# STM32WL5X_CM0P register map
File version: 2.1
CPU: CM0 r0p1, little endian, MPU, no FPU, 4 interrupt priority bits
Registers are 32-bit, read-write, reset 0x0 unless marked. A register's access mark holds for its fields unless they carry their own. Offsets are from the block's base; [hi:lo] are bit positions; {n}, {i} and the like mark numbered series; 'fields as' and 'values as' point back to an identical list.

## RCC — Reset and clock control
Base 0x58000000
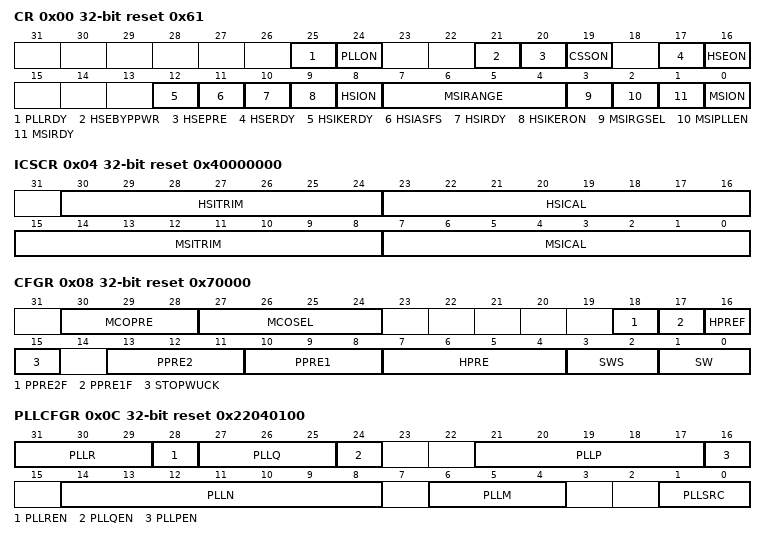
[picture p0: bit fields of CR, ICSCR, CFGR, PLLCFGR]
0x00 CR access per field reset 0x61 — Clock control register
  [25] PLLRDY ro — Main PLL clock ready flag
    0=Unlocked (PLL unlocked); 1=Locked (PLL Locked)
  [24] PLLON rw — Main PLL enable
    0=Off (Main PLL Off); 1=On (Main PLL On)
  [21] HSEBYPPWR rw — Enable HSE32 VDDTCXO output on package pin PB0-VDDTCXO.
    0=PB0 (PB0 selected); 1=VDDTCXO (VDDTCXO selected)
  [20] HSEPRE rw — HSE32 sysclk prescaler
    0=Div1 (SYSCLK not divided (HSE32)); 1=Div2 (SYSCLK divided by two (HSE32/2))
  [19] CSSON rw — HSE32 Clock security system enable
    0=Disabled (HSE32 CSS off); 1=Enabled (HSE32 CSS on if the HSE32 oscillator is stable and off if not)
  [17] HSERDY ro — HSE32 clock ready flag
    0=NotReady (HSE32 oscillator not ready); 1=Ready (HSE32 oscillator ready)
  [16] HSEON rw — HSE32 clock enable
    0=Disabled (HSE32 oscillator for CPU disabled); 1=Enabled (HSE32 oscillator for CPU enabled)
  [12] HSIKERDY ro — HSI16 kernel clock ready flag for peripherals requests.
    0=NotReady (HSI16 oscillator not ready); 1=Ready (HSI16 oscillator ready)
  [11] HSIASFS rw — HSI16 automatic start from Stop
    0=Disabled (HSI16 not enabled by hardware when exiting Stop modes with MSI as wakeup clock); 1=Enabled (HSI16 enabled by hardware when exiting Stop mode with MSI as wakeup clock)
  [10] HSIRDY ro — HSI16 clock ready flag. (After wakeup from Stop this bit will be read 1 once the HSI16 is ready)
    values as HSIKERDY
  [9] HSIKERON rw — HSI16 always enable for peripheral kernel clocks.
    0=NotForced (No effect on HSI16 oscillator); 1=Forced (HSI16 oscillator forced on even in Stop modes)
  [8] HSION rw — HSI16 clock enable
    0=Disabled (HSI16 oscillator off); 1=Enabled (HSI16 oscillator on)
  [7:4] MSIRANGE rw — MSI clock ranges
    0=Range100K (range 0 around 100 kHz); 1=Range200K (range 1 around 200 kHz); 2=Range400K (range 2 around 400 kHz); 3=Range800K (range 3 around 800 kHz); 4=Range1M (range 4 around 1 MHz); 5=Range2M (range 5 around 2 MHz); 6=Range4M (range 6 around 4 MHz (reset value)); 7=Range8M (range 7 around 8 MHz); 8=Range16M (range 8 around 16 MHz); 9=Range24M (range 9 around 24 MHz); 10=Range32M (range 10 around 32 MHz); 11=Range48M (range 11 around 48 MHz)
  [3] MSIRGSEL rw — MSI range control selection
    0=CSR (MSI frequency range defined by MSISRANGE[3:0] in the RCC_CSR register); 1=CR (MSI frequency range defined by MSIRANGE[3:0] in the RCC_CR register)
  [2] MSIPLLEN rw — MSI clock PLL enable
    0=Off (MSI PLL Off); 1=On (MSI PLL On)
  [1] MSIRDY ro — MSI clock ready flag (After reset this bit will be read 1 once the MSI is ready)
    0=NotReady (MSI oscillator not ready); 1=Ready (MSI oscillator ready)
  [0] MSION rw — MSI clock enable
    0=Disabled (MSI oscillator off); 1=Enabled (MSI oscillator on)
0x04 ICSCR access per field reset 0x40000000 — Internal clock sources calibration register
  [30:24] HSITRIM rw range 0..63 — HSI16 clock trimming
  [23:16] HSICAL ro — HSI16 clock calibration
  [15:8] MSITRIM rw — MSI clock trimming
  [7:0] MSICAL ro — MSI clock calibration
0x08 CFGR access per field reset 0x70000 — Clock configuration register
  [30:28] MCOPRE rw — Microcontroller clock output prescaler
    0=Div1 (No division); 1=Div2 (Division by 2); 2=Div4 (Division by 4); 3=Div8 (Division by 8); 4=Div16 (Division by 16)
  [27:24] MCOSEL rw — Microcontroller clock output
    0=NoClock; 1=SYSCLK (SYSCLK clock selected); 2=MSI (MSI oscillator clock selected); 3=HSI16 (HSI16 oscillator clock selected); 4=HSE32 (HSE32 oscillator clock selected); 5=PLLR (Main PLLRCLK clock selected); 6=LSI (LSI oscillator clock selected); 8=LSE (LSE oscillator clock selected); 13=PLLP (Main PLLPCLK clock selected); 14=PLLQ (Main PLLQCLK clock selected)
  [18] PPRE2F ro — PCLK2 prescaler flag (APB2)
    0=NotApplied (PCLK2 prescaler value not yet applied); 1=Applied (PCLK2 prescaler value applied)
  [17] PPRE1F ro — PCLK1 prescaler flag (APB1)
    0=NotApplied (PCLK1 prescaler value not yet applied); 1=Applied (PCLK1 prescaler value applied)
  [16] HPREF ro — HCLK1 prescaler flag (CPU1, AHB1, AHB2, and SRAM1)
    0=NotApplied (HCLK1 prescaler value not yet applied); 1=Applied (HCLK1 prescaler value applied)
  [15] STOPWUCK rw — Wakeup from Stop and CSS backup clock selection
    0=MSI (MSI oscillator selected as wakeup from stop clock and CSS backup clock); 1=HSI16 (HSI16 oscillator selected as wakeup from stop clock and CSS backup clock)
  [13:11] PPRE2 rw — PCLK2 high-speed prescaler (APB2)
    4=Div2 (HCLK divided by 2); 5=Div4 (HCLK divided by 4); 6=Div8 (HCLK divided by 8); 7=Div16 (HCLK divided by 16); other=Div1 (HCLK not divided)
  [10:8] PPRE1 rw — PCLK1 low-speed prescaler (APB1)
    values as PPRE2
  [7:4] HPRE rw — HCLK1 prescaler (CPU1, AHB1, AHB2, and SRAM1.)
    1=Div3 (SYSCLK divided by 3); 2=Div5 (SYSCLK divided by 5); 5=Div6 (SYSCLK divided by 6); 6=Div10 (SYSCLK divided by 10); 7=Div32 (SYSCLK divided by 32); 8=Div2 (SYSCLK divided by 2); 9=Div4 (SYSCLK divided by 4); 10=Div8 (SYSCLK divided by 8); 11=Div16 (SYSCLK divided by 16); 12=Div64 (SYSCLK divided by 64); 13=Div128 (SYSCLK divided by 128); 14=Div256 (SYSCLK divided by 256); 15=Div512 (SYSCLK divided by 512); other=Div1 (SYSCLK not divided)
  [3:2] SWS ro — System clock switch status
    0=MSI (MSI oscillator used as system clock); 1=HSI16 (HSI16 oscillator used as system clock); 2=HSE32 (HSE32 oscillator used as system clock); 3=PLLR (PLLRCLK used as system clock)
  [1:0] SW rw — System clock switch
    values as SWS
0x0C PLLCFGR reset 0x22040100 — PLL configuration register
  [31:29] PLLR — Main PLL division factor for PLLRCLK
    {v}=Div{v+1} (PLL = VCO/(N+1)) (v=1..7)
  [28] PLLREN — Main PLL PLLRCLK output enable
    0=Disabled (PLLCLK output disabled); 1=Enabled (PLLCLK output enabled)
  [27:25] PLLQ — Main PLL division factor for PLLQCLK
    {v}=Div{v+1} (PLL = VCO/(N+1)) (v=1..7)
  [24] PLLQEN — Main PLL PLLQCLK output enable
    values as PLLREN
  [21:17] PLLP — Main PLL division factor for PLLPCLK.
    {v}=Div{v+1} (PLL = VCO/(N+1)) (v=1..31)
  [16] PLLPEN — Main PLL PLLPCLK output enable
    values as PLLREN
  [14:8] PLLN range 6..127 — Main PLL multiplication factor for VCO
  [6:4] PLLM — Division factor for the main PLL input clock
    {v}=Div{v+1} (VCO input = PLL input / PLLM) (v=0..7)
  [1:0] PLLSRC — Main PLL entry clock source
    0=No clock sent to PLL; 1=MSI (MSI clock selected as PLL clock entry); 2=HSI16 (HSI16 clock selected as PLL clock entry); 3=HSE32 (HSE32 clock selected as PLL clock entry)
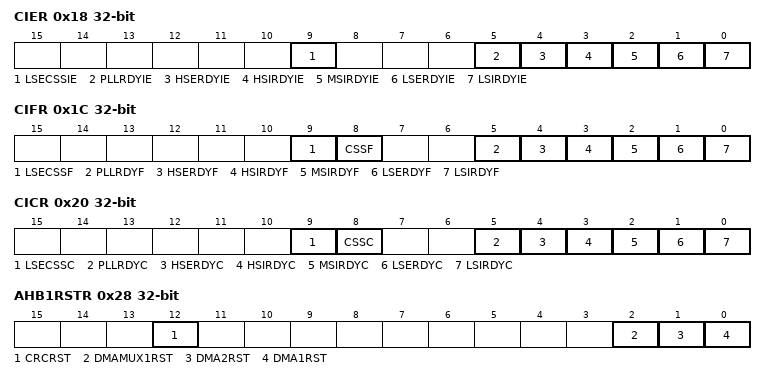
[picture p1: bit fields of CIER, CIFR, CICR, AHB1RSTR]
0x18 CIER — Clock interrupt enable register
  [all] fields
    0=Disabled (Interrupt disabled); 1=Enabled (Interrupt enabled)
  [9] LSECSSIE — LSE clock security system interrupt enable
  [5] PLLRDYIE — PLL ready interrupt enable
  [4] HSERDYIE — HSE32 ready interrupt enable
  [3] HSIRDYIE — HSI16 ready interrupt enable
  [2] MSIRDYIE — MSI ready interrupt enable
  [1] LSERDYIE — LSE ready interrupt enable
  [0] LSIRDYIE — LSI ready interrupt enable
0x1C CIFR ro — Clock interrupt flag register
  [all] fields
    0=NotInterrupted; 1=Interrupted
  [9] LSECSSF — LSE Clock security system interrupt flag
  [8] CSSF — HSE32 Clock security system interrupt flag
  [5] PLLRDYF — PLL ready interrupt flag
  [4] HSERDYF — HSE32 ready interrupt flag
  [3] HSIRDYF — HSI16 ready interrupt flag
  [2] MSIRDYF — MSI ready interrupt flag
  [1] LSERDYF — LSE ready interrupt flag
  [0] LSIRDYF — LSI ready interrupt flag
0x20 CICR wo — Clock interrupt clear register
  [all] fields
    1=Clear interrupt flag
  [9] LSECSSC — LSE Clock security system interrupt clear
  [8] CSSC — HSE32 Clock security system interrupt clear
  [5] PLLRDYC — PLL ready interrupt clear
  [4] HSERDYC — HSE32 ready interrupt clear
  [3] HSIRDYC — HSI16 ready interrupt clear
  [2] MSIRDYC — MSI ready interrupt clear
  [1] LSERDYC — LSE ready interrupt clear
  [0] LSIRDYC — LSI ready interrupt clear
0x28 AHB1RSTR — AHB1 peripheral reset register
  [all] fields
    0=NoReset (No effect); 1=Reset peripheral
  [12] CRCRST — CRC reset
  [2] DMAMUX1RST — DMAMUX1 reset
  [1] DMA2RST — DMA2 reset
  [0] DMA1RST — DMA1 reset
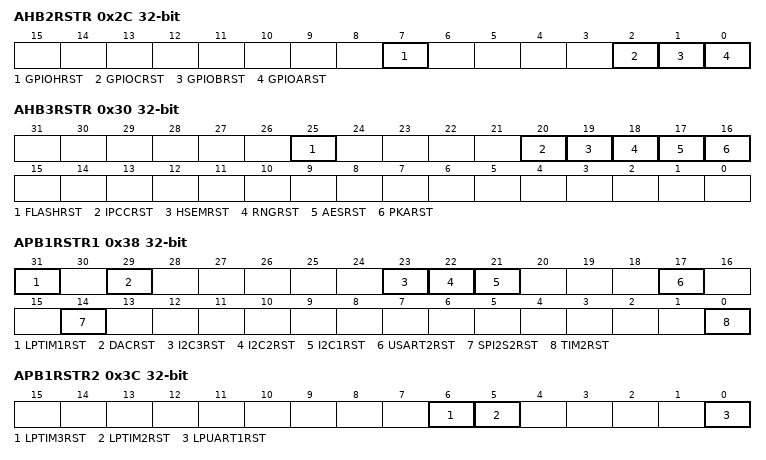
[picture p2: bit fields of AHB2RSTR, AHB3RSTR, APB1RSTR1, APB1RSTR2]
0x2C AHB2RSTR — AHB2 peripheral reset register
  [all] fields
    0=NoReset (No effect); 1=Reset peripheral
  [7] GPIOHRST — IO port H reset
  [2] GPIOCRST — IO port C reset
  [1] GPIOBRST — IO port B reset
  [0] GPIOARST — IO port A reset
0x30 AHB3RSTR — AHB3 peripheral reset register
  [all] fields
    0=NoReset (No effect); 1=Reset peripheral
  [25] FLASHRST — Flash interface reset
  [20] IPCCRST
  [19] HSEMRST
  [18] RNGRST
  [17] AESRST
  [16] PKARST
0x38 APB1RSTR1 — APB1 peripheral reset register 1
  [all] fields
    0=NoReset (No effect); 1=Reset peripheral
  [31] LPTIM1RST — Low Power Timer 1 reset
  [29] DACRST — DAC1 reset
  [23] I2C3RST — I2C3 reset
  [22] I2C2RST — I2C2 reset
  [21] I2C1RST — I2C1 reset
  [17] USART2RST — USART2 reset
  [14] SPI2S2RST — SPI2S2 reset
  [0] TIM2RST — TIM2 timer reset
0x3C APB1RSTR2 — APB1 peripheral reset register 2
  [all] fields
    0=NoReset (No effect); 1=Reset peripheral
  [6] LPTIM3RST — Low-power timer 3 reset
  [5] LPTIM2RST — Low-power timer 2 reset
  [0] LPUART1RST — Low-power UART 1 reset
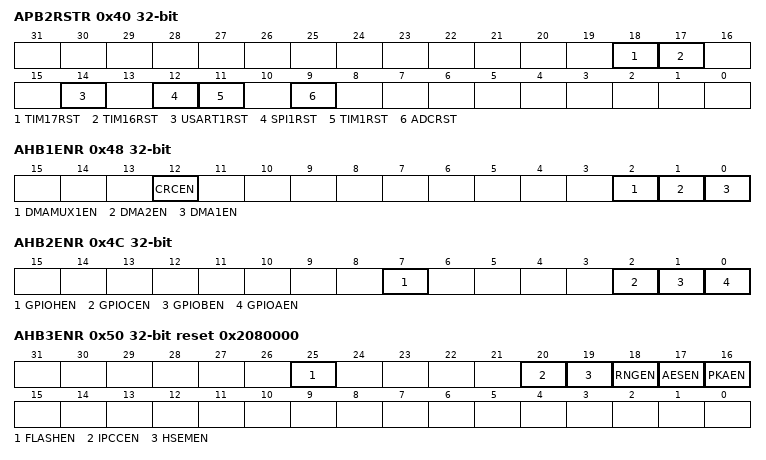
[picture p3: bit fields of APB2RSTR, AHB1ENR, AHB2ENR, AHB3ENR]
0x40 APB2RSTR — APB2 peripheral reset register
  [18] TIM17RST — TIM17 timer reset
  [17] TIM16RST — TIM16 timer reset
  [14] USART1RST — USART1 reset
  [12] SPI1RST — SPI1 reset
  [11] TIM1RST — TIM1 timer reset
  [9] ADCRST — ADC reset
0x44 APB3RSTR — APB3 peripheral reset register
  [0] SUBGHZSPIRST — Sub-GHz radio SPI reset
0x48 AHB1ENR — AHB1 peripheral clock enable register
  [all] fields
    0=Disabled (Clock disabled); 1=Enabled (Clock enabled)
  [12] CRCEN — CPU1 CRC clock enable
  [2] DMAMUX1EN — CPU1 DMAMUX1 clock enable
  [1] DMA2EN — CPU1 DMA2 clock enable
  [0] DMA1EN — CPU1 DMA1 clock enable
0x4C AHB2ENR — AHB2 peripheral clock enable register
  [all] fields
    0=Disabled (Clock disabled); 1=Enabled (Clock enabled)
  [7] GPIOHEN — CPU1 IO port H clock enable
  [2] GPIOCEN — CPU1 IO port C clock enable
  [1] GPIOBEN — CPU1 IO port B clock enable
  [0] GPIOAEN — CPU1 IO port A clock enable
0x50 AHB3ENR reset 0x2080000 — AHB3 peripheral clock enable register
  [all] fields
    0=Disabled (Clock disabled); 1=Enabled (Clock enabled)
  [25] FLASHEN — CPU1 Flash interface clock enable
  [20] IPCCEN
  [19] HSEMEN
  [18] RNGEN
  [17] AESEN
  [16] PKAEN
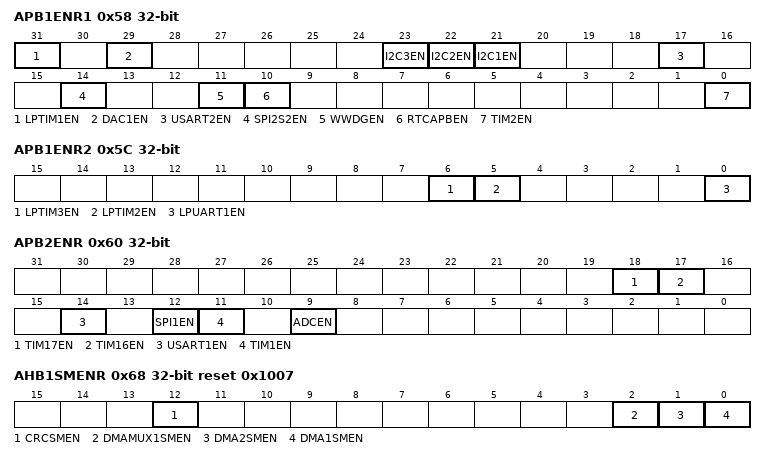
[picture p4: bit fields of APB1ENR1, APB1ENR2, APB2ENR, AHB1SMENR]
0x58 APB1ENR1 — APB1 peripheral clock enable register 1
  [all] fields
    0=Disabled (Clock disabled); 1=Enabled (Clock enabled)
  [31] LPTIM1EN — CPU1 Low power timer 1 clocks enable
  [29] DAC1EN — CPU1 DAC1 clock enable
  [23] I2C3EN — CPU1 I2C3 clocks enable
  [22] I2C2EN — CPU1 I2C2 clocks enable
  [21] I2C1EN — CPU1 I2C1 clocks enable
  [17] USART2EN — CPU1 USART2 clock enable
  [14] SPI2S2EN — CPU1 SPI2S2 clock enable
  [11] WWDGEN — CPU1 Window watchdog clock enable
  [10] RTCAPBEN — CPU1 RTC APB clock enable
  [0] TIM2EN — CPU1 TIM2 timer clock enable
0x5C APB1ENR2 — APB1 peripheral clock enable register 2
  [all] fields
    0=Disabled (Clock disabled); 1=Enabled (Clock enabled)
  [6] LPTIM3EN — CPU1 Low power timer 3 clocks enable
  [5] LPTIM2EN — CPU1 Low power timer 2 clocks enable
  [0] LPUART1EN — CPU1 Low power UART 1 clocks enable
0x60 APB2ENR — APB2 peripheral clock enable register
  [all] fields
    0=Disabled (Clock disabled); 1=Enabled (Clock enabled)
  [18] TIM17EN — CPU1 TIM17 timer clock enable
  [17] TIM16EN — CPU1 TIM16 timer clock enable
  [14] USART1EN — CPU1 USART1clocks enable
  [12] SPI1EN — CPU1 SPI1 clock enable
  [11] TIM1EN — CPU1 TIM1 timer clock enable
  [9] ADCEN — CPU1 ADC clocks enable
0x64 APB3ENR — APB3 peripheral clock enable register
  [0] SUBGHZSPIEN — sub-GHz radio SPI clock enable
    0=Disabled (Clock disabled); 1=Enabled (Clock enabled)
0x68 AHB1SMENR reset 0x1007 — AHB1 peripheral clocks enable in Sleep modes register
  [12] CRCSMEN — CRC clock enable during CPU1 CSleep mode.
  [2] DMAMUX1SMEN — DMAMUX1 clock enable during CPU1 CSleep mode.
  [1] DMA2SMEN — DMA2 clock enable during CPU1 CSleep mode
  [0] DMA1SMEN — DMA1 clock enable during CPU1 CSleep mode.
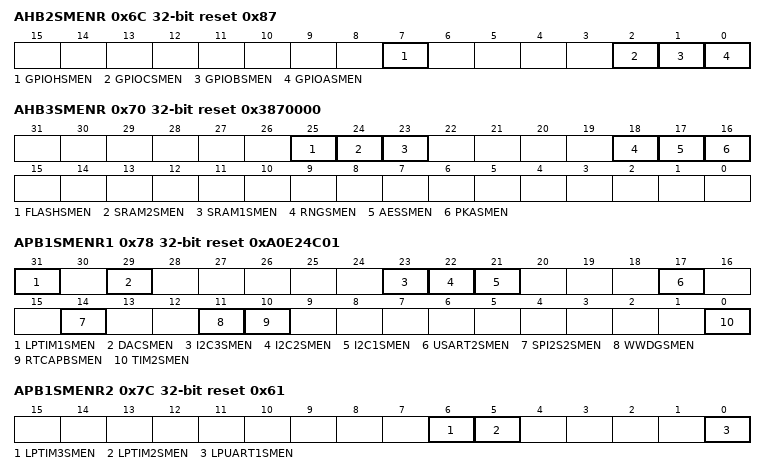
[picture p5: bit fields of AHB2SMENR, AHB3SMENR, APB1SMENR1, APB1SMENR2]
0x6C AHB2SMENR reset 0x87 — AHB2 peripheral clocks enable in Sleep modes register
  [7] GPIOHSMEN — IO port H clock enable during CPU1 CSleep mode.
  [2] GPIOCSMEN — IO port C clock enable during CPU1 CSleep mode.
  [1] GPIOBSMEN — IO port B clock enable during CPU1 CSleep mode.
  [0] GPIOASMEN — IO port A clock enable during CPU1 CSleep mode.
0x70 AHB3SMENR reset 0x3870000 — AHB3 peripheral clocks enable in Sleep and Stop modes register
  [25] FLASHSMEN — Flash interface clock enable during CPU1 CSleep mode.
  [24] SRAM2SMEN — SRAM2 memory interface clock enable during CPU1 CSleep mode
  [23] SRAM1SMEN — SRAM1 interface clock enable during CPU1 CSleep mode.
  [18] RNGSMEN — True RNG clocks enable during CPU1 Csleep and CStop modes
  [17] AESSMEN — AES accelerator clock enable during CPU1 CSleep mode.
  [16] PKASMEN — PKA accelerator clock enable during CPU1 CSleep mode.
0x78 APB1SMENR1 reset 0xA0E24C01 — APB1 peripheral clocks enable in Sleep mode register 1
  [all] fields
    0=Disabled (Clock disabled); 1=Enabled (Clock enabled)
  [31] LPTIM1SMEN — Low power timer 1 clock enable during CPU1 Csleep and CStop mode
  [29] DACSMEN — DAC1 clock enable during CPU1 CSleep mode.
  [23] I2C3SMEN — I2C3 clock enable during CPU1 Csleep and CStop modes
  [22] I2C2SMEN — I2C2 clock enable during CPU1 Csleep and CStop modes
  [21] I2C1SMEN — I2C1 clock enable during CPU1 Csleep and CStop modes
  [17] USART2SMEN — USART2 clock enable during CPU1 CSleep mode.
  [14] SPI2S2SMEN — SPI2S2 clock enable during CPU1 CSleep mode.
  [11] WWDGSMEN — Window watchdog clocks enable during CPU1 CSleep mode.
  [10] RTCAPBSMEN — RTC bus clock enable during CPU1 CSleep mode.
  [0] TIM2SMEN — TIM2 timer clock enable during CPU1 CSleep mode.
0x7C APB1SMENR2 reset 0x61 — APB1 peripheral clocks enable in Sleep mode register 2
  [all] fields
    0=Disabled (Clock disabled); 1=Enabled (Clock enabled)
  [6] LPTIM3SMEN — Low power timer 3 clock enable during CPU1 Csleep and CStop modes
  [5] LPTIM2SMEN — Low power timer 2 clock enable during CPU1 Csleep and CStop modes
  [0] LPUART1SMEN — Low power UART 1 clock enable during CPU1 Csleep and CStop modes.
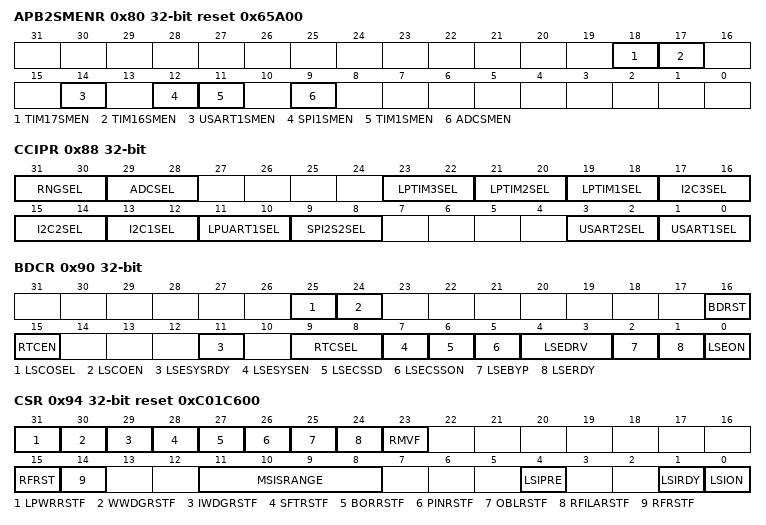
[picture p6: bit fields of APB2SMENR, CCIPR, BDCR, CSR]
0x80 APB2SMENR reset 0x65A00 — APB2 peripheral clocks enable in Sleep mode register
  [18] TIM17SMEN — TIM17 timer clock enable during CPU1 CSleep mode.
  [17] TIM16SMEN — TIM16 timer clock enable during CPU1 CSleep mode.
  [14] USART1SMEN — USART1 clock enable during CPU1 Csleep and CStop modes.
  [12] SPI1SMEN — SPI1 clock enable during CPU1 CSleep mode.
  [11] TIM1SMEN — TIM1 timer clock enable during CPU1 CSleep mode.
  [9] ADCSMEN — ADC clocks enable during CPU1 Csleep and CStop modes
0x84 APB3SMENR reset 0x1 — APB3 peripheral clock enable in Sleep mode register
  [0] SUBGHZSPISMEN — Sub-GHz radio SPI clock enable during Sleep and Stop modes
0x88 CCIPR — Peripherals independent clock configuration register
  [31:30] RNGSEL — RNG clock source selection
    0=PLLQ (PLLQ clock selected); 1=LSI (LSI clock selected); 2=LSE (LSE clock selected); 3=MSI (MSI clock selected)
  [29:28] ADCSEL — ADC clock source selection
    0=No clock selected; 1=HSI16 (HSI16 clock selected); 2=PLLP (PLLP clock selected); 3=SYSCLK (SYSCLK clock selected)
  [23:22] LPTIM3SEL — Low power timer 3 clock source selection
    0=PCLK (PCLK clock selected); 1=LSI (LSI clock selected); 2=HSI16 (HSI16 clock selected); 3=LSE (LSE clock selected)
  [21:20] LPTIM2SEL — Low power timer 2 clock source selection
    values as LPTIM3SEL
  [19:18] LPTIM1SEL — Low power timer 1 clock source selection
    values as LPTIM3SEL
  [17:16] I2C3SEL — I2C3 clock source selection
    0=PCLK (PCLK clock selected); 1=SYSCLK (SYSCLK clock selected); 2=HSI16 (HSI16 clock selected)
  [15:14] I2C2SEL — I2C2 clock source selection
    values as I2C3SEL
  [13:12] I2C1SEL — I2C1 clock source selection
    values as I2C3SEL
  [11:10] LPUART1SEL — LPUART1 clock source selection
    0=PCLK (PCLK clock selected); 1=SYSCLK (SYSCLK clock selected); 2=HSI16 (HSI16 clock selected); 3=LSE (LSE clock selected)
  [9:8] SPI2S2SEL — SPI2S2 I2S clock source selection
    1=PLLQ (PLLQ clock selected); 2=HSI16 (HSI16 clock selected); 3=I2S (External input I2S_CKIN selected)
  [3:2] USART2SEL — USART2 clock source selection
    values as LPUART1SEL
  [1:0] USART1SEL — USART1 clock source selection
    values as LPUART1SEL
0x90 BDCR access per field — Backup domain control register
  [25] LSCOSEL rw — Low speed clock output selection
    0=LSI (LSI clock selected); 1=LSE (LSE clock selected)
  [24] LSCOEN rw — Low speed clock output enable
    0=Disabled (LSCO disabled); 1=Enabled (LSCO enabled)
  [16] BDRST rw — Backup domain software reset
    0=NotActive (Reset not activated); 1=Reset (Entire Backup domain reset)
  [15] RTCEN rw — RTC clock enable
    0=Disabled (RTC kernel clock disabled); 1=Enabled (RTC kernel clock enabled)
  [11] LSESYSRDY ro — LSE system clock ready
    0=NotReady (LSE system clock not ready); 1=Ready (LSE system clock ready)
  [9:8] RTCSEL rw — RTC clock source selection
    0=NoClock; 1=LSE (LSE oscillator clock selected); 2=LSI (LSI oscillator clock selected); 3=HSE32 (HSE32 oscillator clock divided by 32 selected)
  [7] LSESYSEN rw — LSE system clock enable
    0=Disabled (LSE system clock disabled to USARTx, LPUARTx, LPTIMx, TIMx, RNG, system LSCO, MCO, MSI PLL mode); 1=Enabled (LSE system clock enabled to USARTx, LPUARTx, LPTIMx, TIMx, RNG, system LSCO, MCO, MSI PLL mode)
  [6] LSECSSD ro — CSS on LSE failure Detection
    0=No failure detected on LSE; 1=Failure detected on LSE
  [5] LSECSSON rw — CSS on LSE enable
    0=Disabled (CSS on LSE disabled); 1=Enabled (CSS on LSE enabled)
  [4:3] LSEDRV rw — LSE oscillator drive capability
    0=Low (Xtal mode lower driving capability); 1=MedLow (Xtal mode medium-low driving capability); 2=MedHigh (Xtal mode medium-high driving capability); 3=High (Xtal mode higher driving capability)
  [2] LSEBYP rw — LSE oscillator bypass
    0=Disabled (LSE oscillator not bypassed); 1=Enabled (LSE oscillator bypassed)
  [1] LSERDY ro — LSE oscillator ready
    0=NotReady (LSE oscillator not ready); 1=Ready (LSE oscillator ready)
  [0] LSEON rw — LSE oscillator enable
    0=Off (LSE oscillator off); 1=On (LSE oscillator on)
0x94 CSR access per field reset 0xC01C600 — Control/status register
  [31] LPWRRSTF ro — Low-power reset flag
    0=No reset occurred; 1=Reset occurred
  [30] WWDGRSTF ro — Window watchdog reset flag
    0=No reset occurred; 1=Reset occurred
  [29] IWDGRSTF ro — Independent window watchdog reset flag
    0=No reset occurred; 1=Reset occurred
  [28] SFTRSTF ro — Software reset flag
    0=No reset occurred; 1=Reset occurred
  [27] BORRSTF ro — BOR flag
    0=No reset occurred; 1=Reset occurred
  [26] PINRSTF ro — Pin reset flag
    0=No reset occurred; 1=Reset occurred
  [25] OBLRSTF ro — Option byte loader reset flag
    0=No reset occurred; 1=Reset occurred
  [24] RFILARSTF ro — Radio illegal access flag
    0=NoIllegalCommand (No SUBGHZ radio illegal command occurred); 1=IllegalCommand (SUBGHZ radio illegal command occurred)
  [23] RMVF rw — Remove reset flag
    0=NoEffect; 1=Clear (Reset flags reset)
  [15] RFRST rw — Radio reset
    0=Removed (Sub-GHz radio software reset removed); 1=Reset (Sub-GHz radio software reset active)
  [14] RFRSTF ro — Radio in reset status flag
    0=NoReset (Sub-GHz radio out of reset); 1=Reset (Sub-GHz radio in reset)
  [11:8] MSISRANGE rw — MSI clock ranges
    4=f_1MHz (Range 4 around 1 MHz); 5=f_2MHz (Range 5 around 2 MHz); 6=f_4MHz (Range 6 around 4 MHz (reset value)); 7=f_8MHz (Range 7 around 8 MHz)
  [4] LSIPRE rw — LSI frequency prescaler
    0=Div1 (LSI clock not divided); 1=Div128 (LSI clock divided by 128)
  [1] LSIRDY ro — LSI oscillator ready
    0=NotReady (LSI oscillator not ready); 1=Ready (LSI oscillator ready)
  [0] LSION rw — LSI oscillator enable
    0=Off (LSI oscillator off); 1=On (LSI oscillator on)
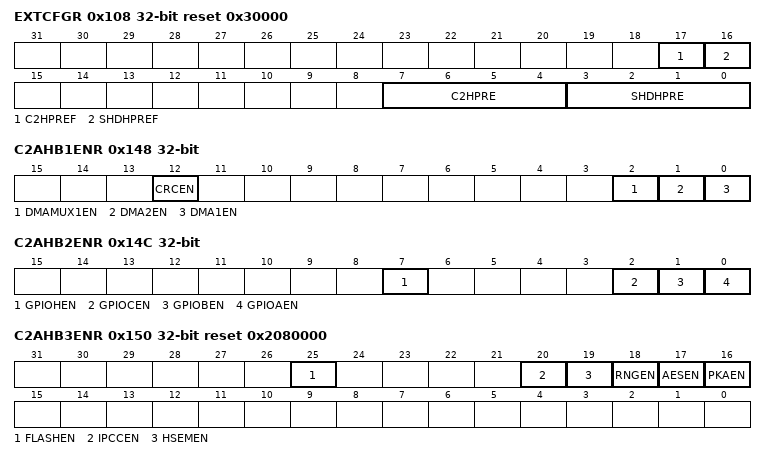
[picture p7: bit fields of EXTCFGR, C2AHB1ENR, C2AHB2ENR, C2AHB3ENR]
0x108 EXTCFGR access per field reset 0x30000 — Extended clock recovery register
  [17] C2HPREF ro — CLK2 prescaler flag (CPU2)
  [16] SHDHPREF ro — HCLK3 shared prescaler flag (AHB3, Flash, and SRAM2)
    0=NotApplied (HCLK3 prescaler value not yet applied); 1=Applied (HCLK3 prescaler value applied)
  [7:4] C2HPRE rw — [dual core device only] HCLK2 prescaler (CPU2)
  [3:0] SHDHPRE rw — HCLK3 shared prescaler (AHB3, Flash, and SRAM2)
    values as CFGR.HPRE
0x148 C2AHB1ENR — CPU2 AHB1 peripheral clock enable register
  [all] fields
    0=Disabled (Clock disabled); 1=Enabled (Clock enabled)
  [12] CRCEN — CPU2 CRC clock enable
  [2] DMAMUX1EN — CPU2 DMAMUX1 clock enable
  [1] DMA2EN — CPU2 DMA2 clock enable
  [0] DMA1EN — CPU2 DMA1 clock enable
0x14C C2AHB2ENR — CPU2 AHB2 peripheral clock enable register
  [all] fields
    0=Disabled (Clock disabled); 1=Enabled (Clock enabled)
  [7] GPIOHEN — CPU2 IO port H clock enable
  [2] GPIOCEN — CPU2 IO port C clock enable
  [1] GPIOBEN — CPU2 IO port B clock enable
  [0] GPIOAEN — CPU2 IO port A clock enable
0x150 C2AHB3ENR reset 0x2080000 — CPU2 AHB3 peripheral clock enable register [dual core device only]
  [all] fields
    0=Disabled (Clock disabled); 1=Enabled (Clock enabled)
  [25] FLASHEN — CPU2 Flash interface clock enable
  [20] IPCCEN — CPU2 IPCC interface clock enable
  [19] HSEMEN — CPU2 HSEM clock enable
  [18] RNGEN — CPU2 True RNG clocks enable
  [17] AESEN — CPU2 AES accelerator clock enable
  [16] PKAEN — CPU2 PKA accelerator clock enable
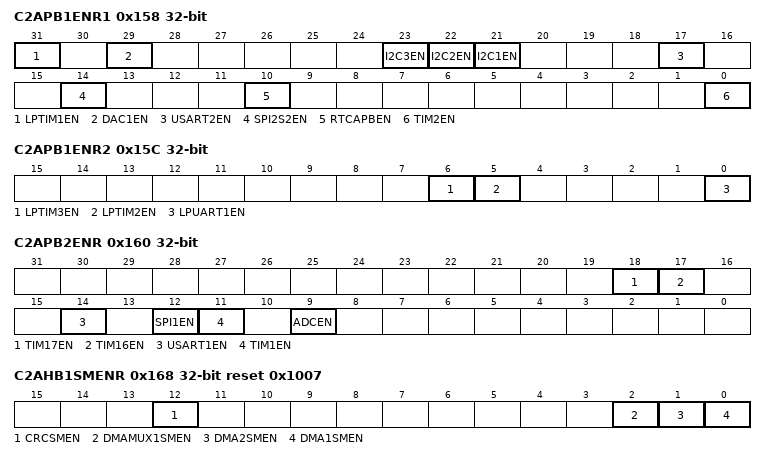
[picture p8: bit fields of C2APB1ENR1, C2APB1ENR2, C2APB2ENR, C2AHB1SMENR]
0x158 C2APB1ENR1 — CPU2 APB1 peripheral clock enable register 1 [dual core device only]
  [all] fields
    0=Disabled (Clock disabled); 1=Enabled (Clock enabled)
  [31] LPTIM1EN — CPU2 Low power timer 1 clocks enable
  [29] DAC1EN — CPU2 DAC1 clock enable
  [23] I2C3EN — CPU2 I2C3 clocks enable
  [22] I2C2EN — CPU2 I2C2 clocks enable
  [21] I2C1EN — CPU2 I2C1 clocks enable
  [17] USART2EN — CPU2 USART2 clock enable
  [14] SPI2S2EN — CPU2 SPI2S2 clock enable
  [10] RTCAPBEN — CPU2 RTC APB clock enable
  [0] TIM2EN — CPU2 TIM2 timer clock enable
0x15C C2APB1ENR2 — CPU2 APB1 peripheral clock enable register 2 [dual core device only]
  [all] fields
    0=Disabled (Clock disabled); 1=Enabled (Clock enabled)
  [6] LPTIM3EN — CPU2 Low power timer 3 clocks enable
  [5] LPTIM2EN — CPU2 Low power timer 2 clocks enable
  [0] LPUART1EN — CPU2 Low power UART 1 clocks enable
0x160 C2APB2ENR — CPU2 APB2 peripheral clock enable register [dual core device only]
  [all] fields
    0=Disabled (Clock disabled); 1=Enabled (Clock enabled)
  [18] TIM17EN — CPU2 TIM17 timer clock enable
  [17] TIM16EN — CPU2 TIM16 timer clock enable
  [14] USART1EN — CPU2 USART1clocks enable
  [12] SPI1EN — CPU2 SPI1 clock enable
  [11] TIM1EN — CPU2 TIM1 timer clock enable
  [9] ADCEN — ADC clocks enable
0x164 C2APB3ENR — CPU2 APB3 peripheral clock enable register [dual core device only]
  [0] SUBGHZSPIEN — CPU2 sub-GHz radio SPI clock enable
    0=Disabled (Clock disabled); 1=Enabled (Clock enabled)
0x168 C2AHB1SMENR reset 0x1007 — CPU2 AHB1 peripheral clocks enable in Sleep modes register [dual core device only]
  [all] fields
    0=Disabled (Clock disabled); 1=Enabled (Clock enabled)
  [12] CRCSMEN — CRC clock enable during CPU2 CSleep mode.
  [2] DMAMUX1SMEN — DMAMUX1 clock enable during CPU2 CSleep mode.
  [1] DMA2SMEN — DMA2 clock enable during CPU2 CSleep mode.
  [0] DMA1SMEN — DMA1 clock enable during CPU2 CSleep mode.
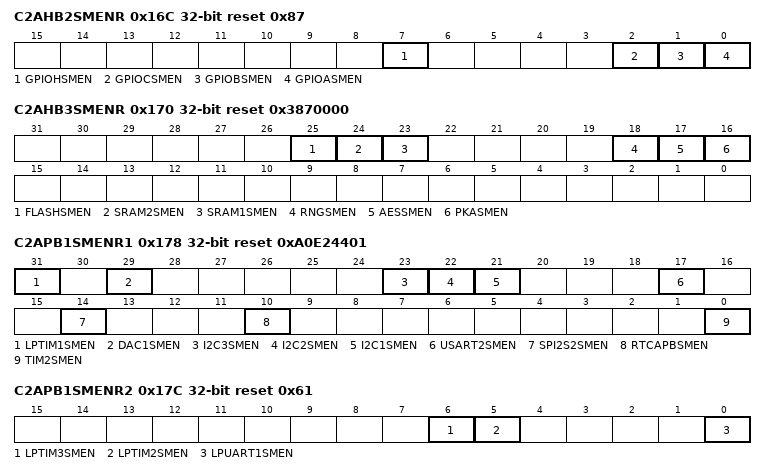
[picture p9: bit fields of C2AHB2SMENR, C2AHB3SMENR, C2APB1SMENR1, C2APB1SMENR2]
0x16C C2AHB2SMENR reset 0x87 — CPU2 AHB2 peripheral clocks enable in Sleep modes register [dual core device only]
  [all] fields
    0=Disabled (Clock disabled); 1=Enabled (Clock enabled)
  [7] GPIOHSMEN — IO port H clock enable during CPU2 CSleep mode.
  [2] GPIOCSMEN — IO port C clock enable during CPU2 CSleep mode.
  [1] GPIOBSMEN — IO port B clock enable during CPU2 CSleep mode.
  [0] GPIOASMEN — IO port A clock enable during CPU2 CSleep mode.
0x170 C2AHB3SMENR reset 0x3870000 — CPU2 AHB3 peripheral clocks enable in Sleep mode register [dual core device only]
  [all] fields
    0=Disabled (Clock disabled); 1=Enabled (Clock enabled)
  [25] FLASHSMEN — Flash interface clock enable during CPU2 CSleep mode.
  [24] SRAM2SMEN — SRAM2 memory interface clock enable during CPU2 CSleep mode.
  [23] SRAM1SMEN — SRAM1 interface clock enable during CPU2 CSleep mode.
  [18] RNGSMEN — True RNG clock enable during CPU2 CSleep and CStop mode.
  [17] AESSMEN — AES accelerator clock enable during CPU2 CSleep mode.
  [16] PKASMEN — PKA accelerator clock enable during CPU2 CSleep mode.
0x178 C2APB1SMENR1 reset 0xA0E24401 — CPU2 APB1 peripheral clocks enable in Sleep mode register 1 [dual core device only]
  [all] fields
    0=Disabled (Clock disabled); 1=Enabled (Clock enabled)
  [31] LPTIM1SMEN — Low power timer 1 clock enable during CPU2 CSleep and CStop mode
  [29] DAC1SMEN — DAC1 clock enable during CPU2 CSleep mode.
  [23] I2C3SMEN — I2C3 clock enable during CPU2 CSleep and CStop modes
  [22] I2C2SMEN — I2C2 clock enable during CPU2 CSleep and CStop modes
  [21] I2C1SMEN — I2C1 clock enable during CPU2 CSleep and CStop modes
  [17] USART2SMEN — USART2 clock enable during CPU2 CSleep mode.
  [14] SPI2S2SMEN — SPI2S2 clock enable during CPU2 CSleep mode.
  [10] RTCAPBSMEN — RTC bus clock enable during CPU2 CSleep mode.
  [0] TIM2SMEN — TIM2 timer clock enable during CPU2 CSleep mode.
0x17C C2APB1SMENR2 reset 0x61 — CPU2 APB1 peripheral clocks enable in Sleep mode register 2 [dual core device only]
  [all] fields
    0=Disabled (Clock disabled); 1=Enabled (Clock enabled)
  [6] LPTIM3SMEN — Low power timer 3 clocks enable during CPU2 CSleep and CStop modes.
  [5] LPTIM2SMEN — Low power timer 2 clocks enable during CPU2 CSleep and CStop modes.
  [0] LPUART1SMEN — Low power UART 1 clock enable during CPU2 CSleep and CStop mode
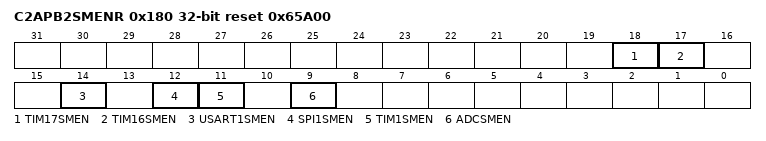
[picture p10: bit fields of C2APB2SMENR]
0x180 C2APB2SMENR reset 0x65A00 — CPU2 APB2 peripheral clocks enable in Sleep mode register [dual core device only]
  [all] fields
    0=Disabled (Clock disabled); 1=Enabled (Clock enabled)
  [18] TIM17SMEN — TIM17 timer clock enable during CPU2 CSleep mode
  [17] TIM16SMEN — TIM16 timer clock enable during CPU2 CSleep mode
  [14] USART1SMEN — USART1clock enable during CPU2 CSleep and CStop mode
  [12] SPI1SMEN — SPI1 clock enable during CPU2 CSleep mode
  [11] TIM1SMEN — TIM1 timer clock enable during CPU2 CSleep mode
  [9] ADCSMEN — ADC clocks enable during CPU2 Csleep and CStop modes
0x184 C2APB3SMENR reset 0x1 — CPU2 APB3 peripheral clock enable in Sleep mode register [dual core device only]
  [0] SUBGHZSPISMEN — sub-GHz radio SPI clock enable during CPU2 CSleep and CStop modes
    0=Disabled (Clock disabled); 1=Enabled (Clock enabled)
